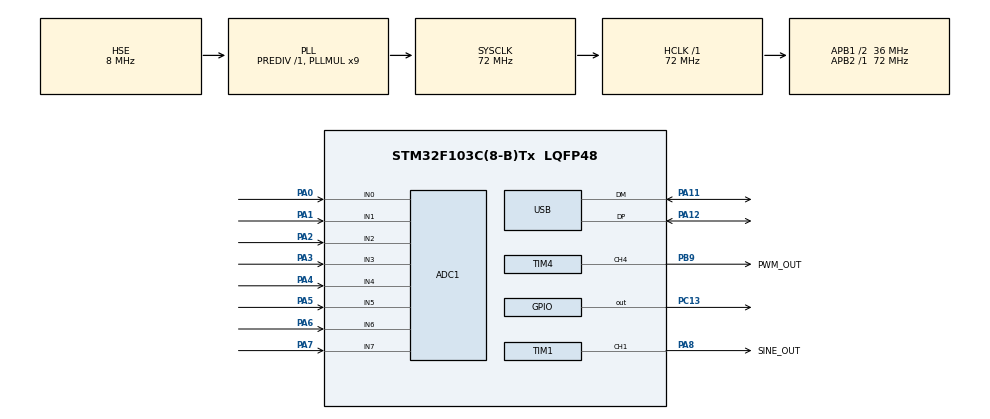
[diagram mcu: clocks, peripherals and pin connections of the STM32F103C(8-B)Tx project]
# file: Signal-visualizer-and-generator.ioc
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ADC1.Channel-10\#ChannelRegularConversion=ADC_CHANNEL_6
ADC1.Channel-11\#ChannelRegularConversion=ADC_CHANNEL_7
ADC1.Channel-4\#ChannelRegularConversion=ADC_CHANNEL_0
ADC1.Channel-5\#ChannelRegularConversion=ADC_CHANNEL_1
ADC1.Channel-6\#ChannelRegularConversion=ADC_CHANNEL_2
ADC1.Channel-7\#ChannelRegularConversion=ADC_CHANNEL_3
ADC1.Channel-8\#ChannelRegularConversion=ADC_CHANNEL_4
ADC1.Channel-9\#ChannelRegularConversion=ADC_CHANNEL_5
ADC1.ContinuousConvMode=ENABLE
ADC1.DiscontinuousConvMode=DISABLE
ADC1.EnableRegularConversion=ENABLE
ADC1.NbrOfConversion=8
ADC1.NbrOfConversionFlag=1
ADC1.Rank-10\#ChannelRegularConversion=7
ADC1.Rank-11\#ChannelRegularConversion=8
ADC1.Rank-4\#ChannelRegularConversion=1
ADC1.Rank-5\#ChannelRegularConversion=2
ADC1.Rank-6\#ChannelRegularConversion=3
ADC1.Rank-7\#ChannelRegularConversion=4
ADC1.Rank-8\#ChannelRegularConversion=5
ADC1.Rank-9\#ChannelRegularConversion=6
ADC1.SamplingTime-10\#ChannelRegularConversion=ADC_SAMPLETIME_13CYCLES_5
ADC1.SamplingTime-11\#ChannelRegularConversion=ADC_SAMPLETIME_13CYCLES_5
ADC1.SamplingTime-4\#ChannelRegularConversion=ADC_SAMPLETIME_13CYCLES_5
ADC1.SamplingTime-5\#ChannelRegularConversion=ADC_SAMPLETIME_13CYCLES_5
ADC1.SamplingTime-6\#ChannelRegularConversion=ADC_SAMPLETIME_13CYCLES_5
ADC1.SamplingTime-7\#ChannelRegularConversion=ADC_SAMPLETIME_13CYCLES_5
ADC1.SamplingTime-8\#ChannelRegularConversion=ADC_SAMPLETIME_13CYCLES_5
ADC1.SamplingTime-9\#ChannelRegularConversion=ADC_SAMPLETIME_13CYCLES_5
ADC1.master=1
Dma.ADC1.0.Direction=DMA_PERIPH_TO_MEMORY
Dma.ADC1.0.Instance=DMA1_Channel1
Dma.ADC1.0.MemDataAlignment=DMA_MDATAALIGN_HALFWORD
Dma.ADC1.0.MemInc=DMA_MINC_ENABLE
Dma.ADC1.0.Mode=DMA_CIRCULAR
Dma.ADC1.0.PeriphDataAlignment=DMA_PDATAALIGN_HALFWORD
Dma.ADC1.0.PeriphInc=DMA_PINC_DISABLE
Dma.ADC1.0.Priority=DMA_PRIORITY_MEDIUM
Dma.Request0=ADC1
Mcu.Family=STM32F1
Mcu.Name=STM32F103C(8-B)Tx
Mcu.Package=LQFP48
NVIC.DMA1_Channel1_IRQn=true\:2\:0\:true\:false\:true\:false\:true\:true
NVIC.PriorityGroup=NVIC_PRIORITYGROUP_4
NVIC.USB_LP_CAN1_RX0_IRQn=true\:1\:0\:true\:false\:true\:false\:true\:true
PA0-WKUP.Signal=ADCx_IN0
PA1.Signal=ADCx_IN1
PA11.Mode=Device
PA11.Signal=USB_DM
PA12.Mode=Device
PA12.Signal=USB_DP
PA13.Mode=Serial_Wire
PA13.Signal=SYS_JTMS-SWDIO
PA14.Mode=Serial_Wire
PA14.Signal=SYS_JTCK-SWCLK
PA2.Signal=ADCx_IN2
PA3.Signal=ADCx_IN3
PA4.Signal=ADCx_IN4
PA5.Signal=ADCx_IN5
PA6.Signal=ADCx_IN6
PA7.Signal=ADCx_IN7
PA8.GPIO_Label=SINE_OUT
PA8.Signal=S_TIM1_CH1
PB9.GPIO_Label=PWM_OUT
PB9.Signal=S_TIM4_CH4
PC13-TAMPER-RTC.Signal=GPIO_Output
PD0-OSC_IN.Mode=HSE-External-Oscillator
PD0-OSC_IN.Signal=RCC_OSC_IN
PD1-OSC_OUT.Mode=HSE-External-Oscillator
PD1-OSC_OUT.Signal=RCC_OSC_OUT
ProjectManager.HeapSize=0x200
ProjectManager.StackSize=0x400
ProjectManager.TargetToolchain=STM32CubeIDE
RCC.ADCPresc=RCC_ADCPCLK2_DIV6
RCC.AHBFreq_Value=72000000
RCC.APB1CLKDivider=RCC_HCLK_DIV2
RCC.APB1Freq_Value=36000000
RCC.APB1TimFreq_Value=72000000
RCC.APB2Freq_Value=72000000
RCC.APB2TimFreq_Value=72000000
RCC.HCLKFreq_Value=72000000
RCC.PLLMUL=RCC_PLL_MUL9
RCC.SYSCLKFreq_VALUE=72000000
RCC.SYSCLKSource=RCC_SYSCLKSOURCE_PLLCLK
RCC.USBFreq_Value=48000000
RCC.USBPrescaler=RCC_USBCLKSOURCE_PLL_DIV1_5
SH.ADCx_IN0.0=ADC1_IN0,IN0
SH.ADCx_IN1.0=ADC1_IN1,IN1
SH.ADCx_IN2.0=ADC1_IN2,IN2
SH.ADCx_IN3.0=ADC1_IN3,IN3
SH.ADCx_IN4.0=ADC1_IN4,IN4
SH.ADCx_IN5.0=ADC1_IN5,IN5
SH.ADCx_IN6.0=ADC1_IN6,IN6
SH.ADCx_IN7.0=ADC1_IN7,IN7
SH.S_TIM1_CH1.0=TIM1_CH1,PWM Generation1 CH1
SH.S_TIM4_CH4.0=TIM4_CH4,PWM Generation4 CH4
TIM1.Channel-PWM\ Generation1\ CH1=TIM_CHANNEL_1
TIM1.Period=99
TIM1.Prescaler=719
TIM4.Channel-PWM\ Generation4\ CH4=TIM_CHANNEL_4
TIM4.Period=99
TIM4.Prescaler=719
USB_DEVICE.CLASS_NAME_FS=CDC
USB_DEVICE.VirtualMode=Cdc
USB_DEVICE.VirtualModeFS=Cdc_FS
VP_TIM1_VS_ClockSourceINT.Mode=Internal
VP_TIM4_VS_ClockSourceINT.Mode=Internal
VP_USB_DEVICE_VS_USB_DEVICE_CDC_FS.Mode=CDC_FS
board=custom

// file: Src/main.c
/* USER CODE BEGIN Header */
/**
 ******************************************************************************
 * @file           : main.c
 * @brief          : Main program body
 ******************************************************************************
 * @attention
 *
 * <h2><center>&copy; Copyright (c) 2019 STMicroelectronics.
 * All rights reserved.</center></h2>
 *
 * This software component is licensed by ST under Ultimate Liberty license
 * SLA0044, the "License"; You may not use this file except in compliance with
 * the License. You may obtain a copy of the License at:
 *                             www.st.com/SLA0044
 *
 ******************************************************************************
 */
/* USER CODE END Header */
#include "main.h"
#include "usb_device.h"

/* USER CODE BEGIN Includes */
#include <application/controller.h>

/* USER CODE END Includes */

ADC_HandleTypeDef hadc1;
DMA_HandleTypeDef hdma_adc1;

TIM_HandleTypeDef htim1;
TIM_HandleTypeDef htim4;

void SystemClock_Config(void);
static void MX_GPIO_Init(void);
static void MX_DMA_Init(void);
static void MX_ADC1_Init(void);
static void MX_TIM4_Init(void);
static void MX_TIM1_Init(void);

int main(void)
{

  /* MCU Configuration--------------------------------------------------------*/

  /* Reset of all peripherals, Initializes the Flash interface and the Systick. */
  HAL_Init();

  /* Configure the system clock */
  SystemClock_Config();

  /* Initialize all configured peripherals */
  MX_GPIO_Init();
  MX_DMA_Init();
  MX_ADC1_Init();
  MX_USB_DEVICE_Init();
  MX_TIM4_Init();
  MX_TIM1_Init();
  /* USER CODE BEGIN 2 */

	controller_init();
  /* USER CODE END 2 */

  /* Infinite loop */
  /* USER CODE BEGIN WHILE */
	while (1)
	{
    controller_handler();
    /* USER CODE END WHILE */

	}
}

void SystemClock_Config(void)
{
  RCC_OscInitTypeDef RCC_OscInitStruct = {0};
  RCC_ClkInitTypeDef RCC_ClkInitStruct = {0};
  RCC_PeriphCLKInitTypeDef PeriphClkInit = {0};

  /** Initializes the RCC Oscillators according to the specified parameters
  * in the RCC_OscInitTypeDef structure.
  */
  RCC_OscInitStruct.OscillatorType = RCC_OSCILLATORTYPE_HSE;
  RCC_OscInitStruct.HSEState = RCC_HSE_ON;
  RCC_OscInitStruct.HSEPredivValue = RCC_HSE_PREDIV_DIV1;
  RCC_OscInitStruct.HSIState = RCC_HSI_ON;
  RCC_OscInitStruct.PLL.PLLState = RCC_PLL_ON;
  RCC_OscInitStruct.PLL.PLLSource = RCC_PLLSOURCE_HSE;
  RCC_OscInitStruct.PLL.PLLMUL = RCC_PLL_MUL9;
  if (HAL_RCC_OscConfig(&RCC_OscInitStruct) != HAL_OK)
  {
    Error_Handler();
  }

  /** Initializes the CPU, AHB and APB buses clocks
  */
  RCC_ClkInitStruct.ClockType = RCC_CLOCKTYPE_HCLK|RCC_CLOCKTYPE_SYSCLK
                              |RCC_CLOCKTYPE_PCLK1|RCC_CLOCKTYPE_PCLK2;
  RCC_ClkInitStruct.SYSCLKSource = RCC_SYSCLKSOURCE_PLLCLK;
  RCC_ClkInitStruct.AHBCLKDivider = RCC_SYSCLK_DIV1;
  RCC_ClkInitStruct.APB1CLKDivider = RCC_HCLK_DIV2;
  RCC_ClkInitStruct.APB2CLKDivider = RCC_HCLK_DIV1;

  if (HAL_RCC_ClockConfig(&RCC_ClkInitStruct, FLASH_LATENCY_2) != HAL_OK)
  {
    Error_Handler();
  }
  PeriphClkInit.PeriphClockSelection = RCC_PERIPHCLK_ADC|RCC_PERIPHCLK_USB;
  PeriphClkInit.AdcClockSelection = RCC_ADCPCLK2_DIV6;
  PeriphClkInit.UsbClockSelection = RCC_USBCLKSOURCE_PLL_DIV1_5;
  if (HAL_RCCEx_PeriphCLKConfig(&PeriphClkInit) != HAL_OK)
  {
    Error_Handler();
  }
}

static void MX_ADC1_Init(void)
{

  ADC_ChannelConfTypeDef sConfig = {0};

  /** Common config
  */
  hadc1.Instance = ADC1;
  hadc1.Init.ScanConvMode = ADC_SCAN_ENABLE;
  hadc1.Init.ContinuousConvMode = ENABLE;
  hadc1.Init.DiscontinuousConvMode = DISABLE;
  hadc1.Init.ExternalTrigConv = ADC_SOFTWARE_START;
  hadc1.Init.DataAlign = ADC_DATAALIGN_RIGHT;
  hadc1.Init.NbrOfConversion = 8;
  if (HAL_ADC_Init(&hadc1) != HAL_OK)
  {
    Error_Handler();
  }

  /** Configure Regular Channel
  */
  sConfig.Channel = ADC_CHANNEL_0;
  sConfig.Rank = ADC_REGULAR_RANK_1;
  sConfig.SamplingTime = ADC_SAMPLETIME_13CYCLES_5;
  if (HAL_ADC_ConfigChannel(&hadc1, &sConfig) != HAL_OK)
  {
    Error_Handler();
  }

  /** Configure Regular Channel
  */
  sConfig.Channel = ADC_CHANNEL_1;
  sConfig.Rank = ADC_REGULAR_RANK_2;
  if (HAL_ADC_ConfigChannel(&hadc1, &sConfig) != HAL_OK)
  {
    Error_Handler();
  }

  /** Configure Regular Channel
  */
  sConfig.Channel = ADC_CHANNEL_2;
  sConfig.Rank = ADC_REGULAR_RANK_3;
  if (HAL_ADC_ConfigChannel(&hadc1, &sConfig) != HAL_OK)
  {
    Error_Handler();
  }

  /** Configure Regular Channel
  */
  sConfig.Channel = ADC_CHANNEL_3;
  sConfig.Rank = ADC_REGULAR_RANK_4;
  if (HAL_ADC_ConfigChannel(&hadc1, &sConfig) != HAL_OK)
  {
    Error_Handler();
  }

  /** Configure Regular Channel
  */
  sConfig.Channel = ADC_CHANNEL_4;
  sConfig.Rank = ADC_REGULAR_RANK_5;
  if (HAL_ADC_ConfigChannel(&hadc1, &sConfig) != HAL_OK)
  {
    Error_Handler();
  }

  /** Configure Regular Channel
  */
  sConfig.Channel = ADC_CHANNEL_5;
  sConfig.Rank = ADC_REGULAR_RANK_6;
  if (HAL_ADC_ConfigChannel(&hadc1, &sConfig) != HAL_OK)
  {
    Error_Handler();
  }

  /** Configure Regular Channel
  */
  sConfig.Channel = ADC_CHANNEL_6;
  sConfig.Rank = ADC_REGULAR_RANK_7;
  if (HAL_ADC_ConfigChannel(&hadc1, &sConfig) != HAL_OK)
  {
    Error_Handler();
  }

  /** Configure Regular Channel
  */
  sConfig.Channel = ADC_CHANNEL_7;
  sConfig.Rank = ADC_REGULAR_RANK_8;
  if (HAL_ADC_ConfigChannel(&hadc1, &sConfig) != HAL_OK)
  {
    Error_Handler();
  }

}

static void MX_TIM1_Init(void)
{

  TIM_ClockConfigTypeDef sClockSourceConfig = {0};
  TIM_MasterConfigTypeDef sMasterConfig = {0};
  TIM_OC_InitTypeDef sConfigOC = {0};
  TIM_BreakDeadTimeConfigTypeDef sBreakDeadTimeConfig = {0};

  htim1.Instance = TIM1;
  htim1.Init.Prescaler = 719;
  htim1.Init.CounterMode = TIM_COUNTERMODE_UP;
  htim1.Init.Period = 99;
  htim1.Init.ClockDivision = TIM_CLOCKDIVISION_DIV1;
  htim1.Init.RepetitionCounter = 0;
  htim1.Init.AutoReloadPreload = TIM_AUTORELOAD_PRELOAD_DISABLE;
  if (HAL_TIM_Base_Init(&htim1) != HAL_OK)
  {
    Error_Handler();
  }
  sClockSourceConfig.ClockSource = TIM_CLOCKSOURCE_INTERNAL;
  if (HAL_TIM_ConfigClockSource(&htim1, &sClockSourceConfig) != HAL_OK)
  {
    Error_Handler();
  }
  if (HAL_TIM_PWM_Init(&htim1) != HAL_OK)
  {
    Error_Handler();
  }
  sMasterConfig.MasterOutputTrigger = TIM_TRGO_RESET;
  sMasterConfig.MasterSlaveMode = TIM_MASTERSLAVEMODE_DISABLE;
  if (HAL_TIMEx_MasterConfigSynchronization(&htim1, &sMasterConfig) != HAL_OK)
  {
    Error_Handler();
  }
  sConfigOC.OCMode = TIM_OCMODE_PWM1;
  sConfigOC.Pulse = 0;
  sConfigOC.OCPolarity = TIM_OCPOLARITY_HIGH;
  sConfigOC.OCNPolarity = TIM_OCNPOLARITY_HIGH;
  sConfigOC.OCFastMode = TIM_OCFAST_DISABLE;
  sConfigOC.OCIdleState = TIM_OCIDLESTATE_RESET;
  sConfigOC.OCNIdleState = TIM_OCNIDLESTATE_RESET;
  if (HAL_TIM_PWM_ConfigChannel(&htim1, &sConfigOC, TIM_CHANNEL_1) != HAL_OK)
  {
    Error_Handler();
  }
  sBreakDeadTimeConfig.OffStateRunMode = TIM_OSSR_DISABLE;
  sBreakDeadTimeConfig.OffStateIDLEMode = TIM_OSSI_DISABLE;
  sBreakDeadTimeConfig.LockLevel = TIM_LOCKLEVEL_OFF;
  sBreakDeadTimeConfig.DeadTime = 0;
  sBreakDeadTimeConfig.BreakState = TIM_BREAK_DISABLE;
  sBreakDeadTimeConfig.BreakPolarity = TIM_BREAKPOLARITY_HIGH;
  sBreakDeadTimeConfig.AutomaticOutput = TIM_AUTOMATICOUTPUT_DISABLE;
  if (HAL_TIMEx_ConfigBreakDeadTime(&htim1, &sBreakDeadTimeConfig) != HAL_OK)
  {
    Error_Handler();
  }
  HAL_TIM_MspPostInit(&htim1);

}

static void MX_TIM4_Init(void)
{

  TIM_ClockConfigTypeDef sClockSourceConfig = {0};
  TIM_MasterConfigTypeDef sMasterConfig = {0};
  TIM_OC_InitTypeDef sConfigOC = {0};

  htim4.Instance = TIM4;
  htim4.Init.Prescaler = 719;
  htim4.Init.CounterMode = TIM_COUNTERMODE_UP;
  htim4.Init.Period = 99;
  htim4.Init.ClockDivision = TIM_CLOCKDIVISION_DIV1;
  htim4.Init.AutoReloadPreload = TIM_AUTORELOAD_PRELOAD_DISABLE;
  if (HAL_TIM_Base_Init(&htim4) != HAL_OK)
  {
    Error_Handler();
  }
  sClockSourceConfig.ClockSource = TIM_CLOCKSOURCE_INTERNAL;
  if (HAL_TIM_ConfigClockSource(&htim4, &sClockSourceConfig) != HAL_OK)
  {
    Error_Handler();
  }
  if (HAL_TIM_PWM_Init(&htim4) != HAL_OK)
  {
    Error_Handler();
  }
  sMasterConfig.MasterOutputTrigger = TIM_TRGO_RESET;
  sMasterConfig.MasterSlaveMode = TIM_MASTERSLAVEMODE_DISABLE;
  if (HAL_TIMEx_MasterConfigSynchronization(&htim4, &sMasterConfig) != HAL_OK)
  {
    Error_Handler();
  }
  sConfigOC.OCMode = TIM_OCMODE_PWM1;
  sConfigOC.Pulse = 0;
  sConfigOC.OCPolarity = TIM_OCPOLARITY_HIGH;
  sConfigOC.OCFastMode = TIM_OCFAST_DISABLE;
  if (HAL_TIM_PWM_ConfigChannel(&htim4, &sConfigOC, TIM_CHANNEL_4) != HAL_OK)
  {
    Error_Handler();
  }
  HAL_TIM_MspPostInit(&htim4);

}

static void MX_DMA_Init(void)
{

  /* DMA controller clock enable */
  __HAL_RCC_DMA1_CLK_ENABLE();

  /* DMA interrupt init */
  /* DMA1_Channel1_IRQn interrupt configuration */
  HAL_NVIC_SetPriority(DMA1_Channel1_IRQn, 2, 0);
  HAL_NVIC_EnableIRQ(DMA1_Channel1_IRQn);

}

static void MX_GPIO_Init(void)
{
  GPIO_InitTypeDef GPIO_InitStruct = {0};

  /* GPIO Ports Clock Enable */
  __HAL_RCC_GPIOC_CLK_ENABLE();
  __HAL_RCC_GPIOD_CLK_ENABLE();
  __HAL_RCC_GPIOA_CLK_ENABLE();
  __HAL_RCC_GPIOB_CLK_ENABLE();

  /*Configure GPIO pin Output Level */
  HAL_GPIO_WritePin(GPIOC, GPIO_PIN_13, GPIO_PIN_RESET);

  /*Configure GPIO pin : PC13 */
  GPIO_InitStruct.Pin = GPIO_PIN_13;
  GPIO_InitStruct.Mode = GPIO_MODE_OUTPUT_PP;
  GPIO_InitStruct.Pull = GPIO_NOPULL;
  GPIO_InitStruct.Speed = GPIO_SPEED_FREQ_LOW;
  HAL_GPIO_Init(GPIOC, &GPIO_InitStruct);

}

void Error_Handler(void)
{
}
